# MEC1723N_B0_LJ register map
Vendor: Microchip Technology; Series: MEC172x; File version: 0
CPU: CM4 r1p0, little endian, MPU, FPU, 3 interrupt priority bits, 172 interrupts
Registers are 32-bit, read-write, reset 0x0 unless marked. A register's access mark holds for its fields unless they carry their own. Offsets are from the block's base; [hi:lo] are bit positions; {n}, {i} and the like mark numbered series; 'fields as' and 'values as' point back to an identical list.

## DMA_MAIN — DMA Main Registers
Base 0x40002400
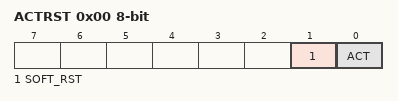
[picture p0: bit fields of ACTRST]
0x00 ACTRST 8-bit — Soft reset the entire module. Enable the blocks operation.
  [1] SOFT_RST — Soft reset the entire module. This bit is self-clearing.
  [0] ACT — Enable the blocks operation. (R/WS) 1=Enable block. Each individual channel must be enabled separately. 0=Disable all channels.
0x04 DATA_PKT ro — Debug register that has the data that is stored in the Data Packet. This data is read data from the currently active transfer source.

## CACHE — This is the CACHE Controller
Base 0x40010000
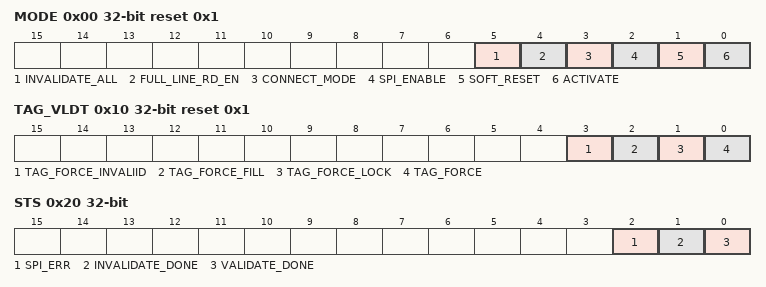
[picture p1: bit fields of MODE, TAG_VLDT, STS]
0x00 MODE reset 0x1 — CACHE MODE register.
  [5] INVALIDATE_ALL — INVALIDATE all CACHE lines.
  [4] FULL_LINE_RD_EN — Full line read enable. 0: Critical section, first and early termination enabled. 1: Critical section, first and early termination disabled.
  [3] CONNECT_MODE — CACHE connection mode. 0: eSPI SAF EC.
  [2] SPI_ENABLE — CACHE SPI Enable. 0: Standard register access. 1: Cache takes over the register interface of eSPI SAF EC
  [1] SOFT_RESET — Soft reset the Cache Controller module. This is self clearing bit. Write Only bit
  [0] ACTIVATE — ACTIVATE 0: Disable block. 1: Enable block.
0x0C SPI_BANK — CSPI Bank. This is ORed into the access address from the processor to create the address sent over to the SPI Flash.
0x10 TAG_VLDT wo reset 0x1 — CACHE TAG VALIDATE register.
  [3] TAG_FORCE_INVALIID — Tag Force Invalid. Will invalidate the address pointed by Tag Validate Address register. 0: No action. 1: Invalidate address.
  [2] TAG_FORCE_FILL — Tag Force Fill. Will cause the cache to immediately fill this cache line. 0: Line will not be filled until it is Miss/Fill. 1: Line will auto fill immediately
  [1] TAG_FORCE_LOCK — Tag Force Lock. Will lock the cache line. 0: Line will not be locked. 1: Line will be locked.
  [0] TAG_FORCE — Tag Force. This bit will allow the cache select a Tag line and allocate the Cache Tag Validate Address to it. 0: No action. 1: A tag line will be allocated
0x14 TAG_VLDT_ADDR — Tag Force Address. This is the address that will be stored in the Tag Line and accessed over SPI if a Tag Force is issued. This address is still used in conjunction with the Cache SPI Bank.This is meant to be an address from the processors perspective. 4 Byte Boundary aligned
0x20 STS — CACHE STATUS register
  [2] SPI_ERR — Indicates CACHE Line Fill error from Flash memory
  [1] INVALIDATE_DONE — Invalidate Done. This bit is set when invalidate command has completed.
  [0] VALIDATE_DONE — Validate Done. This bit is set when Validate command has completed.
0x40 HIT_HI — Hit count Hi. Stores the Hit Count [63:32] of the Cache
0x44 HIT_LOW — Hit count low. Stores the Hit Count [31:0] of the Cache
0x50 MISS_HI — Miss count Hi. Stores the Miss Count [63:32] of the Cache
0x54 MISS_LOW — Miss count low. Stores the Miss Count [31:0] of the Cache
0x60 FILL_HI — Fill count Hi. Stores the Fill Count [63:32] of the Cache
0x64 FILL_LOW — Fill count low. Stores the Fill Count [31:0] of the Cache
{0xC0+4i} RX_BUFFER[{i}] (i=0..15) wo — Rx Buffer0.
0x800 TAG_LOCK0 — Tag Lock0. 0: Tag is not Locked. 1: Tag is Locked.
0x804 TAG_LOCK1 — Tag Lock1. 0: Tag is not Locked. 1: Tag is Locked.
0xC00 TAG_VALID0 ro — Tag Valid0. Tells Line has valid data in the cache. 0: Line is empty. 1: Line is full.
0xC04 TAG_VALID1 ro — Tag Valid1. Tells Line has valid data in the cache. 0: Line is empty. 1: Line is full.
{0x1000+4i} TAG_ADDR[{i}] (i=0..63) ro — Tag Address0.

## ESPI_MSVW07_10 — The ESPI VW Channel permits the System to emulate a set of wires that interconnect the system Core Logic with the EC.
Base 0x400F9C54; register names take the prefix ESPI_MSVW07_1_
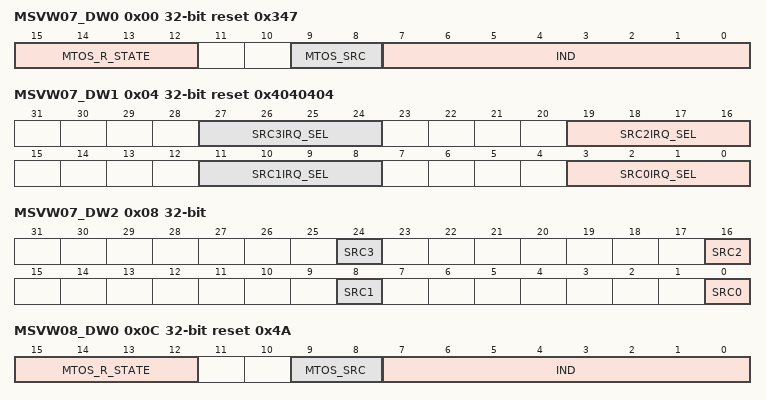
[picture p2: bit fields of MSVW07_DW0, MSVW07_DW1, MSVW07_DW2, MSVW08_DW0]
0x00 MSVW07_DW0 reset 0x347 — Master-to-Slave Virtual Wire 7 Register (DW 0)
  [15:12] MTOS_R_STATE — The four bits in this field are loaded into SRC0, SRC1, SRC2 and SRC3 when the reset signal selected by M2S RESET SRC is asserted. If MTOS_SRC is set for RESET_SYS, the SRC bits are set to the default value of this field, rather than its programmed value, since this field is also reset on RESET_SYS.
  [9:8] MTOS_SRC — This field determines which reset signal in addition to RESET_SYS resets SRC[3:0] in this register: 3=PLTRST 2=RESET_SIO 1=RESET_SYS. This is the only reset signal that will reset the SRC fields. 0=RESET_ESPI.
  [7:0] IND — The Index for SRC0, SRC1, SRC2 and SRC3. When the Index field of an incoming Master-to-Slave Virtual Wire transaction matches this value, the fields SRC0, SRC1, SRC2 and SRC3 are updated by the data contained in the respective bit positions in the transaction. Setting the INDEX field to 0 disables the register from accepting any Virtual Wire traffic from the Master. Setting the INDEX field to 1 is illegal, since INDEX=1 is reserved for Serial IRQ.
0x04 MSVW07_DW1 reset 0x4040404 — Master-to-Slave Virtual Wire 7 Register (DW 1)
  [8n+3:8n] SRC{n}IRQ_SEL (n=0..3) — A change in the value of SRC{n} will generate an interrupt to the EC. Changes in the SRC register value caused by a Reset Event do not generate an interrupt.
0x08 MSVW07_DW2 — Master-to-Slave Virtual Wire 7 Register (DW 2)
  [8n] SRC{n} (n=0..3) — Master-to-Slave data for Bit Position {n} for the virtual wire associated with the index defined by INDEX.
0x0C MSVW08_DW0 reset 0x4A — Master-to-Slave Virtual Wire 8 Register (DW 0)
  fields as MSVW07_DW0
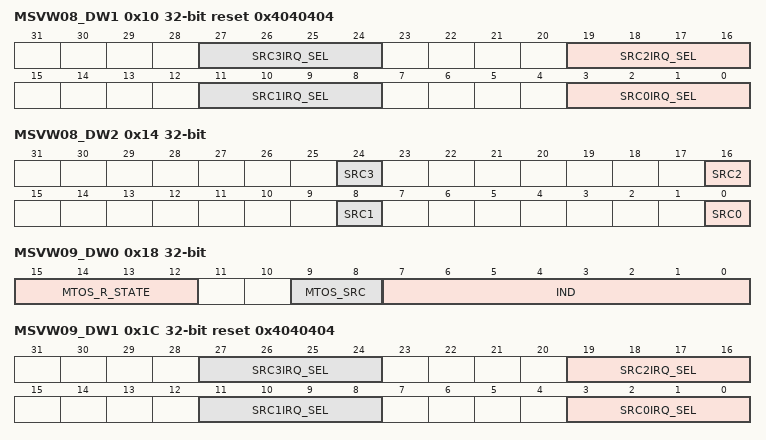
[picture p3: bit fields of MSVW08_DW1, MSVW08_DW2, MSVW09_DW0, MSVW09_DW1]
0x10 MSVW08_DW1 reset 0x4040404 — Master-to-Slave Virtual Wire 8 Register (DW 1)
  fields as MSVW07_DW1
0x14 MSVW08_DW2 — Master-to-Slave Virtual Wire 8 Register (DW 2)
  fields as MSVW07_DW2
0x18 MSVW09_DW0 — Master-to-Slave Virtual Wire 9 Register (DW 0)
  fields as MSVW07_DW0
0x1C MSVW09_DW1 reset 0x4040404 — Master-to-Slave Virtual Wire 9 Register (DW 1)
  fields as MSVW07_DW1
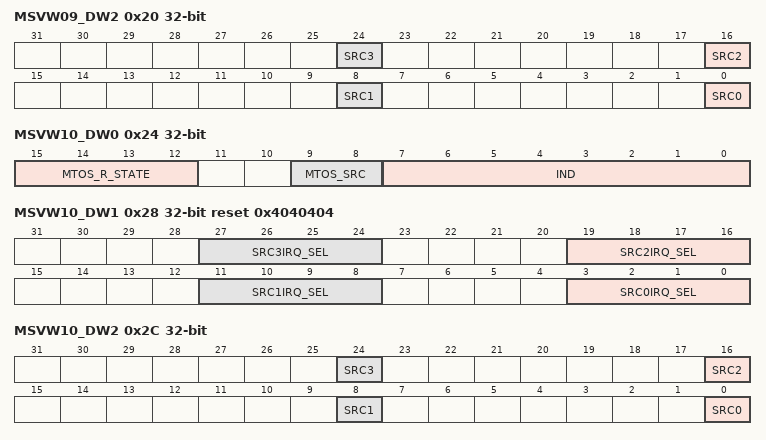
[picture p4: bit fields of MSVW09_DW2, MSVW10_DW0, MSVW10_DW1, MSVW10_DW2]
0x20 MSVW09_DW2 — Master-to-Slave Virtual Wire 9 Register (DW 2)
  fields as MSVW07_DW2
0x24 MSVW10_DW0 — Master-to-Slave Virtual Wire 10 Register (DW 0)
  fields as MSVW07_DW0
0x28 MSVW10_DW1 reset 0x4040404 — Master-to-Slave Virtual Wire 10 Register (DW 1)
  fields as MSVW07_DW1
0x2C MSVW10_DW2 — Master-to-Slave Virtual Wire 10 Register (DW 2)
  fields as MSVW07_DW2
